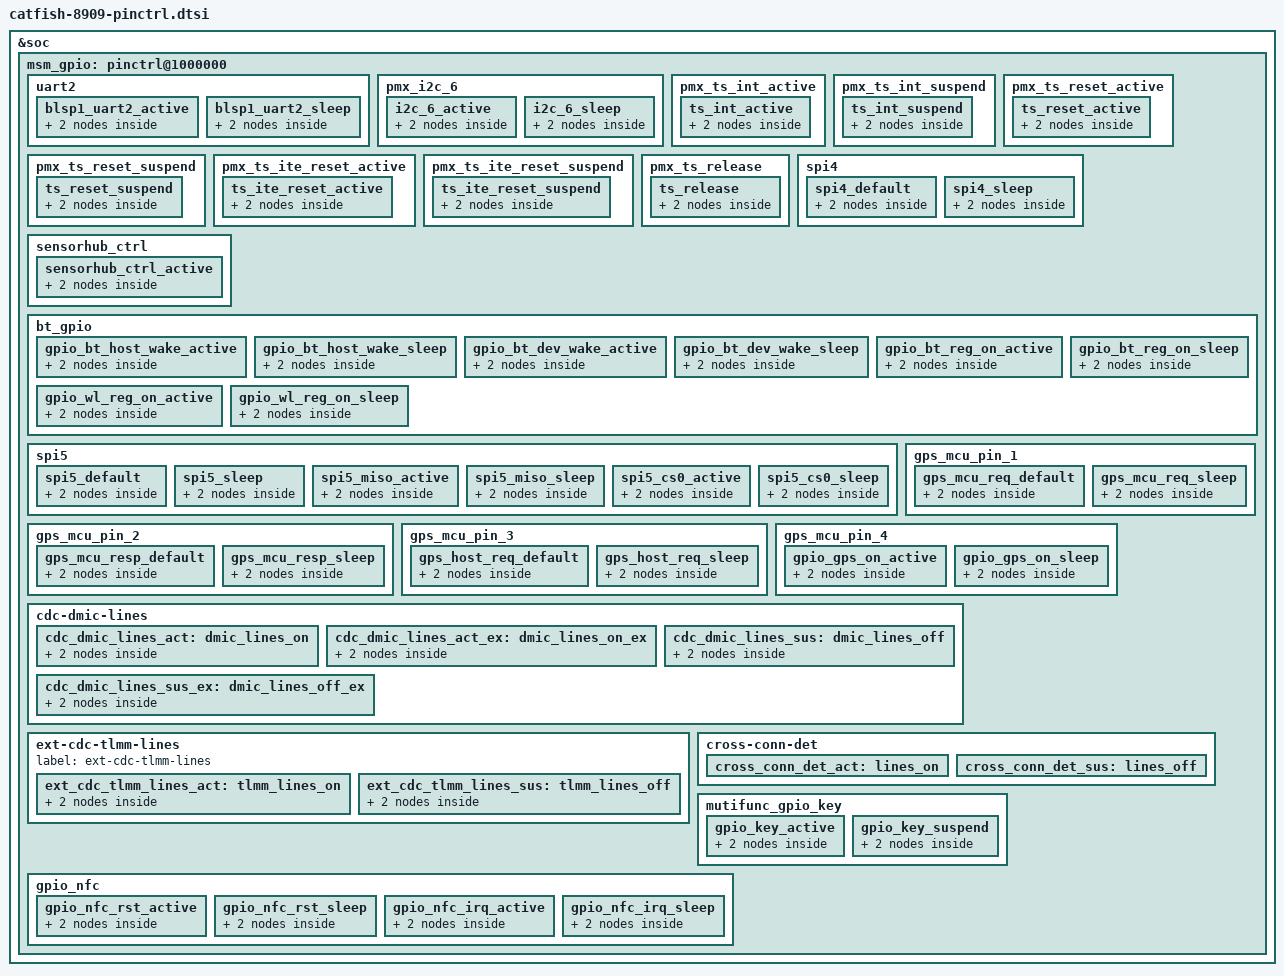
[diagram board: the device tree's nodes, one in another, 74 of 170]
/* add catfish/catshark pinctrl info*/

&soc {
	msm_gpio: pinctrl@1000000 {

		/delete-node/ spi0;
		/delete-node/ pmx_i2c_2;
		/delete-node/ pmx_i2c_3;
		/delete-node/ pmx_i2c_4;
		/delete-node/ pmx_i2c_5;

		uart2 {
			blsp1_uart2_active: blsp1_uart2_active {
				mux {
					pins = "gpio20", "gpio21", "gpio111", "gpio112";
					function = "blsp_uart2";
				};
				config {
					pins = "gpio20", "gpio21", "gpio111", "gpio112";
					drive-strength = <2>;
					bias-disable;
				};
			};
			blsp1_uart2_sleep: blsp1_uart2_sleep {
				mux {
					pins = "gpio20", "gpio21", "gpio111", "gpio112";
					function = "blsp_uart2";
				};
				config {
					pins = "gpio20", "gpio21", "gpio111", "gpio112";
					drive-strength = <2>;
					bias-disable;
				};
			};
		};

		pmx_i2c_6 {
			i2c_6_active: i2c_6_active {
				mux {
					pins = "gpio10", "gpio11";
					function = "blsp_i2c6";
				};
				config {
					pins = "gpio10", "gpio11";
					drive-strength = <2>;
					bias-pull-up;
				};
			};
			i2c_6_sleep: i2c_6_sleep {
				mux {
					pins = "gpio10", "gpio11";
					function = "blsp_i2c6";
				};
				config {
					pins = "gpio10", "gpio11";
					drive-strength = <2>;
					bias-pull-up;
				};
			};
		};

		/* add pingrp for touchscreen */
		pmx_ts_int_active {
			ts_int_active: ts_int_active {
				mux {
					pins = "gpio65";
					function = "gpio";
				};

				config {
					pins = "gpio65";
					drive-strength = <2>;
					bias-pull-up;
				};
			};
		};

		pmx_ts_int_suspend {
			ts_int_suspend: ts_int_suspend {
				mux {
					pins = "gpio65";
					function = "gpio";
				};

				config {
					pins = "gpio65";
					drive-strength = <2>;
					bias-pull-up;
				};
			};
		};

		pmx_ts_reset_active {
			ts_reset_active: ts_reset_active {
				mux {
					pins = "gpio23";
					function = "gpio";
				};

				config {
					pins = "gpio23";
					drive-strength = <2>;
					bias-pull-up;
				};
			};
		};

		pmx_ts_reset_suspend {
			ts_reset_suspend: ts_reset_suspend {
				mux {
					pins = "gpio23";
					function = "gpio";
				};

				config {
					pins = "gpio23";
					drive-strength = <2>;
					bias-pull-up;
				};
			};
		};


		/* Pinctrl dt nodes for reset gpio for ITE tech controller */
		pmx_ts_ite_reset_active {
			ts_ite_reset_active: ts_ite_reset_active {
				mux {
					pins = "gpio23";
					function = "gpio";
				};

				config {
					pins = "gpio23";
					drive-strength = <8>;
					output-high;
				};
			};
		};

		pmx_ts_ite_reset_suspend {
			ts_ite_reset_suspend: ts_ite_reset_suspend {
				mux {
					pins = "gpio23";
					function = "gpio";
				};

				config {
					pins = "gpio23";
					drive-strength = <2>;
					bias-pull-down;
					output-low;
				};
			};
		};

		pmx_ts_release {
			ts_release: ts_release {
				mux {
					pins = "gpio23", "gpio65";
					function = "gpio";
				};

				config {
					pins = "gpio23", "gpio65";
					drive-strength = <2>;
					bias-pull-down;
				};
			};
		};



		spi4 {
			spi4_default: spi4_default {
				/* active state */
				mux {
					/* MOSI, MISO, CLK */
					pins = "gpio12", "gpio13", "gpio15";
					function = "blsp_spi4";
				};

				config {
					pins = "gpio12", "gpio13", "gpio15";
					drive-strength = <12>; /* 12 MA */
					bias-disable = <0>; /* No PULL */
				};
			};

			spi4_sleep: spi4_sleep {
				/* suspended state */
				mux {
					/* MOSI, MISO, CLK */
					pins = "gpio12", "gpio13", "gpio15";
					function = "blsp_spi4";
				};

				config {
					pins = "gpio12", "gpio13", "gpio15";
					drive-strength = <12>; /* 12 MA */
					bias-disable = <0>; /* No PULL */
				};
			};
		};

		sensorhub_ctrl {
		/* NRST, BOOT0, AP2SH, SH2AP, SH2APNW */
			sensorhub_ctrl_active: sensorhub_ctrl_active {
				mux {
					pins = "gpio97", "gpio96", "gpio90", \
						"gpio71", "gpio72","gpio70", \
						"gpio73", "gpio8", "gpio9", \
						"gpio99", "gpio110";
					function = "gpio";
				};

				config {
					pins = "gpio97", "gpio96", "gpio90", \
						"gpio71", "gpio72","gpio70", \
						"gpio73", "gpio8", "gpio9", \
						"gpio99", "gpio110";
					drive-strength = <2>;
					bias-disable;
				};
			};
		};

		bt_gpio {
			gpio_bt_host_wake_active: gpio_bt_host_wake_active {
				mux {
					pins = "gpio31";
					function = "gpio";
				};
				config {
					pins = "gpio31";
					drive-strength = <2>;
					bias-pull-down;
				};
			};

			gpio_bt_host_wake_sleep: gpio_bt_host_wake_sleep {
				mux {
					pins = "gpio31";
					function = "gpio";
				};
				config {
					pins = "gpio31";
					drive-strength = <2>;
					bias-pull-down;
				};
			};

			gpio_bt_dev_wake_active: gpio_bt_dev_wake_active {
				mux {
					pins = "gpio32";
					function = "gpio";
				};
				config {
					pins = "gpio32";
					drive-strength = <2>;
					output-high;
					bias-disable;
				};
			};

			gpio_bt_dev_wake_sleep: gpio_bt_dev_wake_sleep {
				mux {
					pins = "gpio32";
					function = "gpio";
				};
				config {
					pins = "gpio32";
					drive-strength = <2>;
					output-high;
					bias-disable;
				};
			};

			gpio_bt_reg_on_active: gpio_bt_reg_on_active {
				mux {
					pins = "gpio34";
					function = "gpio";
				};
				config {
					pins = "gpio34";
					drive-strength = <2>;
					bias-pull-down;
				};
			};

			gpio_bt_reg_on_sleep: gpio_bt_reg_on_sleep {
				mux {
					pins = "gpio34";
					function = "gpio";
				};
				config {
					pins = "gpio34";
					drive-strength = <2>;
					bias-pull-down;
				};
			};

			gpio_wl_reg_on_active: gpio_wl_reg_on_active {
				mux {
					pins = "gpio33";
					function = "gpio";
				};
				config {
					pins = "gpio33";
					drive-strength = <2>;
					bias-pull-down;
				};
			};

			gpio_wl_reg_on_sleep: gpio_wl_reg_on_sleep {
				mux {
					pins = "gpio33";
					function = "gpio";
				};
				config {
					pins = "gpio33";
					drive-strength = <2>;
					bias-pull-down;
				};
			};

		};

		spi5 {
			spi5_default: spi5_default {
				mux {
					pins = "gpio16", "gpio19";
					function = "blsp_spi5";
				};
				config {
					pins = "gpio16", "gpio19";
					drive-strength = <12>; /* 12 MA */
					bias-disable; /* No PULL */
				};
			};
			spi5_sleep: spi5_sleep {
				mux {
					pins = "gpio16", "gpio19";
					function = "gpio";
				};
				config {
					pins = "gpio16", "gpio19";
					drive-strength = <2>; /* 2 MA */
					bias-pull-down; /* pull down */
				};
			};
			spi5_miso_active: spi5_miso_active {
				mux {
					pins = "gpio17";
					function = "blsp_spi5";
				};
				config {
					pins = "gpio17";
					drive-strength = <2>;
					bias-disable;
				};
			};
			spi5_miso_sleep: spi5_miso_sleep {
				mux {
					pins = "gpio17";
					function = "gpio";
				};
				config {
					pins = "gpio17";
					drive-strength = <2>;
					bias-disable;
				};
			};
			spi5_cs0_active: spi5_cs0_active {
				mux {
					pins = "gpio18";
					function = "blsp_spi5";
				};
				config {
					pins = "gpio18";
					drive-strength = <2>;
					bias-disable;
				};
			};
			spi5_cs0_sleep: spi5_cs0_sleep {
				mux {
					pins = "gpio18";
					function = "gpio";
				};
				config {
					pins = "gpio18";
					drive-strength = <2>;
					bias-pull-up;
				};
			};
		};

		gps_mcu_pin_1 {
			gps_mcu_req_default: gps_mcu_req_default {
				mux {
					pins = "gpio27";
					function = "gpio";
				};
				config {
					pins = "gpio27";
					drive-strength = <2>; /* 2 MA */
				};
			};
			gps_mcu_req_sleep: gps_mcu_req_sleep {
				mux {
					pins = "gpio27";
					function = "gpio";
				};
				config {
					pins = "gpio27";
					drive-strength = <2>; /* 2 MA */
				};
			};
		};
		gps_mcu_pin_2 {
			gps_mcu_resp_default: gps_mcu_resp_default {
				mux {
					pins = "gpio28";
					function = "gpio";
				};
				config {
					pins = "gpio28";
					drive-strength = <4>; /* 2 MA */
					input-enable;
					bias-pull-up;
				};
			};
			gps_mcu_resp_sleep: gps_mcu_resp_sleep {
				mux {
					pins = "gpio28";
					function = "gpio";
				};
				config {
					pins = "gpio28";
					drive-strength = <2>; /* 2 MA */
					input-enable;
					bias-pull-up;
				};
			};
		};
		gps_mcu_pin_3 {
			gps_host_req_default: gps_host_req_default {
				mux {
					pins = "gpio94";
					function = "gpio";
				};
				config {
					pins = "gpio94";
					drive-strength = <2>; /* 2 MA */
				};
			};
			gps_host_req_sleep: gps_host_req_sleep {
				mux {
					pins = "gpio94";
					function = "gpio";
				};
				config {
					pins = "gpio94";
					drive-strength = <2>; /* 2 MA */
				};
			};
		};

		gps_mcu_pin_4 {
			gpio_gps_on_active: gpio_gps_on_active {
				mux {
					pins = "gpio74";
					function = "gpio";
				};

				config {
					pins = "gpio74";
					drive-strength = <2>;
					bias-disable;
				};
			};

			gpio_gps_on_sleep: gpio_gps_on_sleep {
				mux {
					pins = "gpio74";
					function = "gpio";
				};

				config {
					pins = "gpio74";
					drive-strength = <2>;
					bias-disable;
				};
			};
		};
		cdc-dmic-lines {
			cdc_dmic_lines_act: dmic_lines_on {
				mux {
					pins = "gpio4";
					function = "dmic0_clk";
				};

				config {
					pins = "gpio4";
					drive-strength = <8>;
				};
			};
			cdc_dmic_lines_act_ex: dmic_lines_on_ex {
				mux {
					pins = "gpio5";
					function = "dmic0_data";
				};

				config {
					pins = "gpio5";
					drive-strength = <8>;
				};
			};
			cdc_dmic_lines_sus: dmic_lines_off {
				mux {
					pins = "gpio4";
					function = "dmic0_clk";
				};

				config {
					pins = "gpio4";
					drive-strength = <2>;
					bias-disable;
				};
			};
			cdc_dmic_lines_sus_ex: dmic_lines_off_ex {
				mux {
					pins = "gpio5";
					function = "dmic0_data";
				};

				config {
					pins = "gpio5";
					drive-strength = <2>;
					bias-disable;
				};
			};
		};
		ext-cdc-tlmm-lines {
			label = "ext-cdc-tlmm-lines";
			ext_cdc_tlmm_lines_act: tlmm_lines_on {
				mux {
					pins = "gpio1", "gpio0", "gpio2", "gpio3";
					function = "sec_mi2s";
				};
				config {
					pins = "gpio1", "gpio0", "gpio2", "gpio3";
					drive-strength = <8>;
					bias-pull-none;
				};
			};
			ext_cdc_tlmm_lines_sus: tlmm_lines_off {
				mux {
					pins = "gpio1", "gpio0", "gpio2", "gpio3";
					function = "sec_mi2s";
				};
				config {
					pins = "gpio1", "gpio0", "gpio2", "gpio3";
					drive-strength = <2>;
					bias-disable;
				};
			};
		};
		cross-conn-det{
			cross_conn_det_act: lines_on {
				/delete-node/ mux;
				/delete-node/ config;
			};

			cross_conn_det_sus: lines_off {
				/delete-node/ mux;
				/delete-node/ config;
			};
		};
		/delete-node/ tpiu_setb_1;
		/delete-node/ tpiu_setb_2;
		/delete-node/ vdd_spkdrv;

		/delete-node/ tlmm_gpio_key;
		mutifunc_gpio_key {
			gpio_key_active: gpio_key_active {
				mux {
					pins = "gpio98";
					function = "gpio";
				};

				config {
					pins = "gpio98";
					drive-strength = <2>;
					bias-pull-up;
				};
			};

			gpio_key_suspend: gpio_key_suspend {
				mux {
					pins = "gpio98";
					function = "gpio";
				};

				config {
					pins = "gpio98";
					drive-strength = <2>;
					bias-pull-up;
				};
			};
		};
		gpio_nfc{

			gpio_nfc_rst_active: gpio_nfc_rst_active {
				mux {
					pins = "gpio36";
					function = "gpio";
				};

				config {
					pins = "gpio36";
					drive-strength = <2>;
					output-low;
				};
			};

			gpio_nfc_rst_sleep: gpio_nfc_rst_sleep {
				mux {
					pins = "gpio36";
					function = "gpio";
				};

				config {
					pins = "gpio36";
					drive-strength = <2>;
					output-low;
				};
			};
			gpio_nfc_irq_active: gpio_nfc_irq_active {
				mux {
					pins = "gpio92";
					function = "gpio";
				};

				config {
					pins = "gpio92";
					drive-strength = <2>;
					bias-disable;
					/* input-enable; */
				};
			};

			gpio_nfc_irq_sleep: gpio_nfc_irq_sleep {
				mux {
					pins = "gpio92";
					function = "gpio";
				};

				config {
					pins = "gpio92";
					drive-strength = <2>;
					bias-disable;
					/* input-enable; */
				};
			};
		};

	};
};
